VERSION "CHUFENG J1939 CAN database (generated from XTOOL HD_CHUFENGDEV data)"

NS_ :

BS_:

BU_: BMS MCU VCU ICM AC CPS ADAS BAT BMSW

BO_ 2364539985 ICM_F004: 8 ICM
 SG_ ICM_F00451_01_0A : 24|16@1+ (0.5,-16000) [-16000|16767.5] "rpm" ICM

BO_ 2365529937 BMS_FF1F: 8 BMS
 SG_ BMS_FF1F51_01_01 : 6|2@1+ (1,0) [0|3] "" BMS

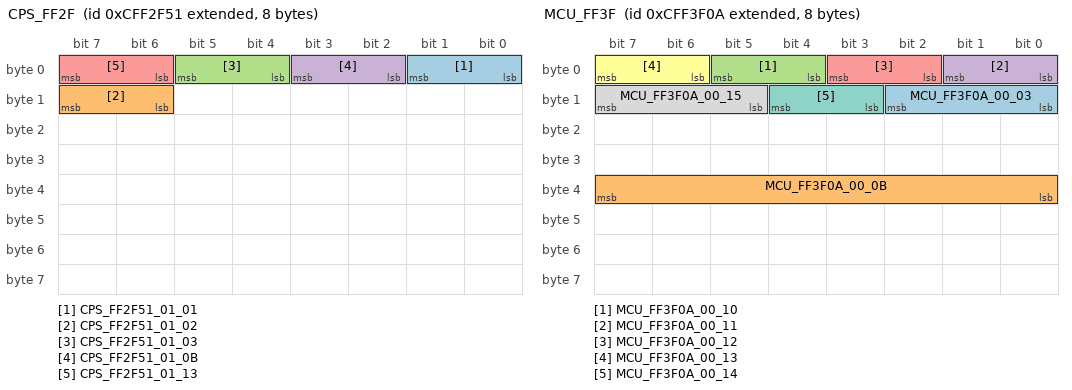
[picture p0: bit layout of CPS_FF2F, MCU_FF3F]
BO_ 2365534033 CPS_FF2F: 8 CPS
 SG_ CPS_FF2F51_01_01 : 0|2@1+ (1,0) [0|3] "" CPS
 SG_ CPS_FF2F51_01_02 : 14|2@1+ (1,0) [0|3] "" CPS
 SG_ CPS_FF2F51_01_03 : 4|2@1+ (1,0) [0|3] "" CPS
 SG_ CPS_FF2F51_01_0B : 2|2@1+ (1,0) [0|3] "" CPS
 SG_ CPS_FF2F51_01_13 : 6|2@1+ (1,0) [0|3] "" CPS

BO_ 2365537802 MCU_FF3E: 8 MCU
 SG_ MCU_FF3E0A_00_09 : 0|16@1+ (0.5,-16000) [-16000|16767.5] "rpm" MCU

BO_ 2365538058 MCU_FF3F: 8 MCU
 SG_ MCU_FF3F0A_00_03 : 8|3@1+ (1,0) [0|7] "" MCU
 SG_ MCU_FF3F0A_00_0B : 32|8@1+ (1,-125) [-125|130] "%" MCU
 SG_ MCU_FF3F0A_00_10 : 4|2@1+ (1,0) [0|3] "" MCU
 SG_ MCU_FF3F0A_00_11 : 0|2@1+ (1,0) [0|3] "" MCU
 SG_ MCU_FF3F0A_00_12 : 2|2@1+ (1,0) [0|3] "" MCU
 SG_ MCU_FF3F0A_00_13 : 6|2@1+ (1,0) [0|3] "" MCU
 SG_ MCU_FF3F0A_00_14 : 11|2@1+ (1,0) [0|3] "" MCU
 SG_ MCU_FF3F0A_00_15 : 13|3@1+ (1,0) [0|7] "" MCU

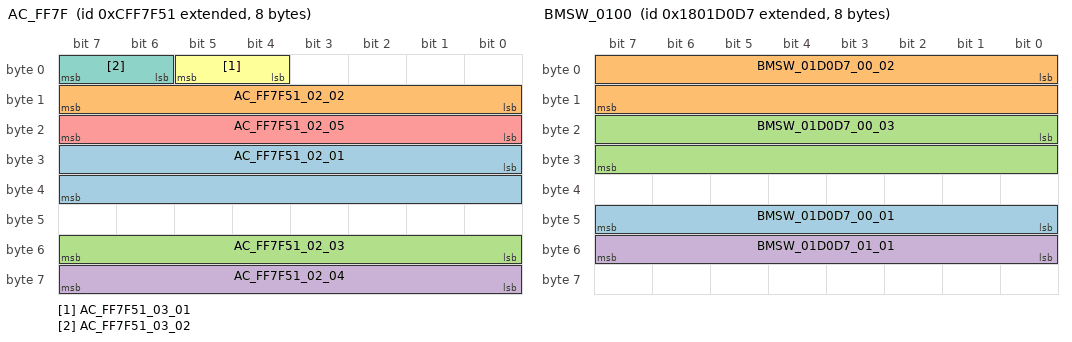
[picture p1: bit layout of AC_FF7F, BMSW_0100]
BO_ 2365554513 AC_FF7F: 8 AC
 SG_ AC_FF7F51_02_01 : 24|16@1+ (0.25,0) [0|16383.75] "rpm" AC
 SG_ AC_FF7F51_02_02 : 8|8@1+ (0.4,0) [0|102] "%" AC
 SG_ AC_FF7F51_02_03 : 48|8@1+ (200,0) [0|51000] "W" AC
 SG_ AC_FF7F51_02_04 : 56|8@1+ (200,0) [0|51000] "W" AC
 SG_ AC_FF7F51_02_05 : 16|8@1+ (1,-40) [-40|215] "℃" AC
 SG_ AC_FF7F51_03_01 : 4|2@1+ (1,0) [0|3] "" AC
 SG_ AC_FF7F51_03_02 : 6|2@1+ (1,0) [0|3] "" AC

BO_ 2550255831 BMSW_0100: 8 BMSW
 SG_ BMSW_01D0D7_00_01 : 40|8@1+ (1,0) [0|255] "" BMSW
 SG_ BMSW_01D0D7_00_02 : 0|16@1+ (1,0) [0|65535] "KΩ" BMSW
 SG_ BMSW_01D0D7_00_03 : 16|16@1+ (1,0) [0|65535] "KΩ" BMSW
 SG_ BMSW_01D0D7_01_01 : 48|8@1+ (1,0) [0|255] "" BMSW

BO_ 2550265081 ADAS_0100: 8 ADAS
 SG_ ADAS_01F4F9_02_01 : 8|8@1+ (1,0) [0|255] "" ADAS
 SG_ ADAS_01F4F9_02_02 : 0|8@1+ (1,0) [0|255] "" ADAS

BO_ 2565865553 ICM_F000: 8 ICM
 SG_ ICM_F00051_02_02 : 26|2@1+ (1,0) [0|3] "" ICM

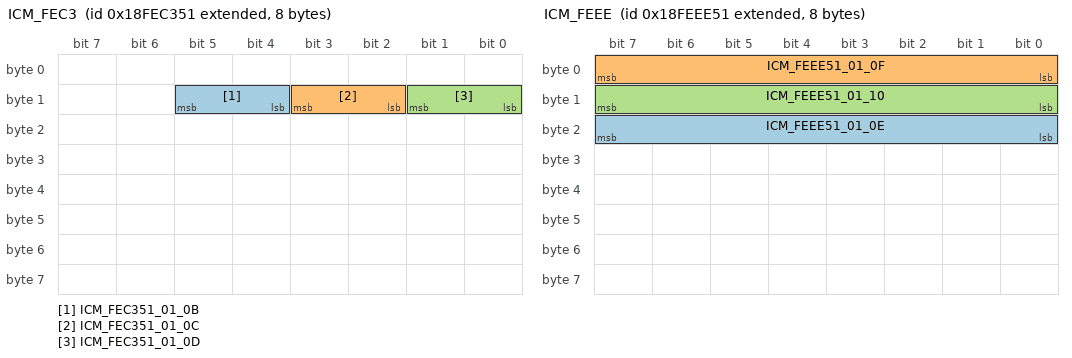
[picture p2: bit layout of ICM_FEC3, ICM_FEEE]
BO_ 2566832977 ICM_FEC3: 8 ICM
 SG_ ICM_FEC351_01_0B : 12|2@1+ (1,0) [0|3] "" ICM
 SG_ ICM_FEC351_01_0C : 10|2@1+ (1,0) [0|3] "" ICM
 SG_ ICM_FEC351_01_0D : 8|2@1+ (1,0) [0|3] "" ICM

BO_ 2566843985 ICM_FEEE: 8 ICM
 SG_ ICM_FEEE51_01_0E : 16|8@1+ (1,-40) [-40|215] "℃" ICM
 SG_ ICM_FEEE51_01_0F : 0|8@1+ (1,-40) [-40|215] "℃" ICM
 SG_ ICM_FEEE51_01_10 : 8|8@1+ (1,-40) [-40|215] "℃" ICM

BO_ 2566844753 ICM_FEF1: 8 ICM
 SG_ ICM_FEF151_01_01 : 8|16@1+ (0.00390625,0) [0|255.996094] "km/h" ICM

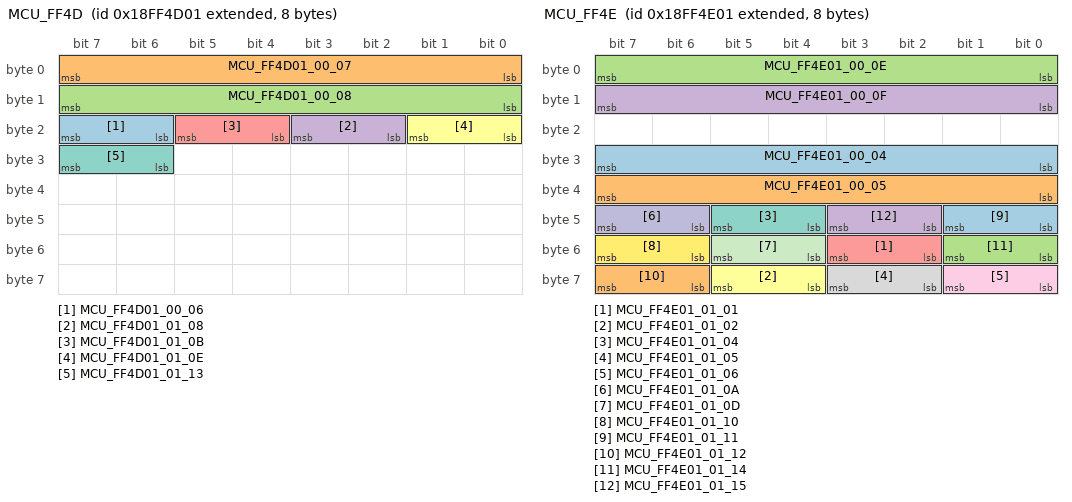
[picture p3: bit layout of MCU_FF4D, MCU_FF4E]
BO_ 2566868225 MCU_FF4D: 8 MCU
 SG_ MCU_FF4D01_00_06 : 22|2@1+ (1,0) [0|3] "" MCU
 SG_ MCU_FF4D01_00_07 : 0|8@1+ (1,0) [0|255] "" MCU
 SG_ MCU_FF4D01_00_08 : 8|8@1+ (1,0) [0|255] "" MCU
 SG_ MCU_FF4D01_01_08 : 18|2@1+ (1,0) [0|3] "" MCU
 SG_ MCU_FF4D01_01_0B : 20|2@1+ (1,0) [0|3] "" MCU
 SG_ MCU_FF4D01_01_0E : 16|2@1+ (1,0) [0|3] "" MCU
 SG_ MCU_FF4D01_01_13 : 30|2@1+ (1,0) [0|3] "" MCU

BO_ 2566868481 MCU_FF4E: 8 MCU
 SG_ MCU_FF4E01_00_04 : 24|8@1+ (1,-125) [-125|130] "%" MCU
 SG_ MCU_FF4E01_00_05 : 32|8@1+ (1,-125) [-125|130] "%" MCU
 SG_ MCU_FF4E01_00_0E : 0|8@1+ (1,-40) [-40|215] "℃" MCU
 SG_ MCU_FF4E01_00_0F : 8|8@1+ (1,-40) [-40|215] "℃" MCU
 SG_ MCU_FF4E01_01_01 : 50|2@1+ (1,0) [0|3] "" MCU
 SG_ MCU_FF4E01_01_02 : 60|2@1+ (1,0) [0|3] "" MCU
 SG_ MCU_FF4E01_01_04 : 44|2@1+ (1,0) [0|3] "" MCU
 SG_ MCU_FF4E01_01_05 : 58|2@1+ (1,0) [0|3] "" MCU
 SG_ MCU_FF4E01_01_06 : 56|2@1+ (1,0) [0|3] "" MCU
 SG_ MCU_FF4E01_01_0A : 46|2@1+ (1,0) [0|3] "" MCU
 SG_ MCU_FF4E01_01_0D : 52|2@1+ (1,0) [0|3] "" MCU
 SG_ MCU_FF4E01_01_10 : 54|2@1+ (1,0) [0|3] "" MCU
 SG_ MCU_FF4E01_01_11 : 40|2@1+ (1,0) [0|3] "" MCU
 SG_ MCU_FF4E01_01_12 : 62|2@1+ (1,0) [0|3] "" MCU
 SG_ MCU_FF4E01_01_14 : 48|2@1+ (1,0) [0|3] "" MCU
 SG_ MCU_FF4E01_01_15 : 42|2@1+ (1,0) [0|3] "" MCU

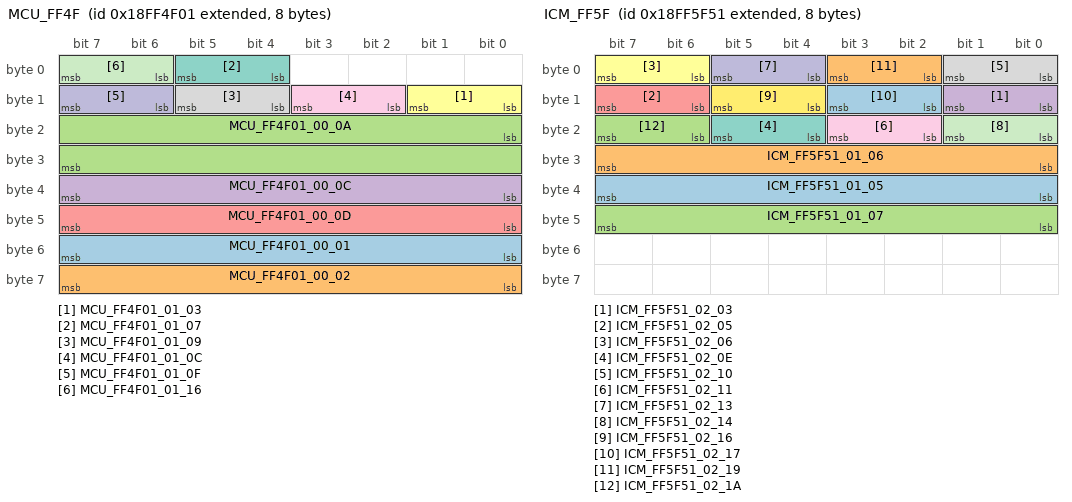
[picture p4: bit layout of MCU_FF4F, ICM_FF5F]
BO_ 2566868737 MCU_FF4F: 8 MCU
 SG_ MCU_FF4F01_00_01 : 48|8@1+ (3.2,0) [0|816] "V" MCU
 SG_ MCU_FF4F01_00_02 : 56|8@1+ (4,-500) [-500|520] "A" MCU
 SG_ MCU_FF4F01_00_0A : 16|16@1+ (0.5,-16000) [-16000|16767.5] "rpm" MCU
 SG_ MCU_FF4F01_00_0C : 32|8@1+ (1,-125) [-125|130] "%" MCU
 SG_ MCU_FF4F01_00_0D : 40|8@1+ (1,-125) [-125|130] "%" MCU
 SG_ MCU_FF4F01_01_03 : 8|2@1+ (1,0) [0|3] "" MCU
 SG_ MCU_FF4F01_01_07 : 4|2@1+ (1,0) [0|3] "" MCU
 SG_ MCU_FF4F01_01_09 : 12|2@1+ (1,0) [0|3] "" MCU
 SG_ MCU_FF4F01_01_0C : 10|2@1+ (1,0) [0|3] "" MCU
 SG_ MCU_FF4F01_01_0F : 14|2@1+ (1,0) [0|3] "" MCU
 SG_ MCU_FF4F01_01_16 : 6|2@1+ (1,0) [0|3] "" MCU

BO_ 2566872913 ICM_FF5F: 8 ICM
 SG_ ICM_FF5F51_01_05 : 32|8@1+ (4,-500) [-500|520] "A" ICM
 SG_ ICM_FF5F51_01_06 : 24|8@1+ (3.2,0) [0|816] "V" ICM
 SG_ ICM_FF5F51_01_07 : 40|8@1+ (2,0) [0|510] "km" ICM
 SG_ ICM_FF5F51_02_03 : 8|2@1+ (1,0) [0|3] "" ICM
 SG_ ICM_FF5F51_02_05 : 14|2@1+ (1,0) [0|3] "" ICM
 SG_ ICM_FF5F51_02_06 : 6|2@1+ (1,0) [0|3] "" ICM
 SG_ ICM_FF5F51_02_0E : 20|2@1+ (1,0) [0|3] "" ICM
 SG_ ICM_FF5F51_02_10 : 0|2@1+ (1,0) [0|3] "" ICM
 SG_ ICM_FF5F51_02_11 : 18|2@1+ (1,0) [0|3] "" ICM
 SG_ ICM_FF5F51_02_13 : 4|2@1+ (1,0) [0|3] "" ICM
 SG_ ICM_FF5F51_02_14 : 16|2@1+ (1,0) [0|3] "" ICM
 SG_ ICM_FF5F51_02_16 : 12|2@1+ (1,0) [0|3] "" ICM
 SG_ ICM_FF5F51_02_17 : 10|2@1+ (1,0) [0|3] "" ICM
 SG_ ICM_FF5F51_02_19 : 2|2@1+ (1,0) [0|3] "" ICM
 SG_ ICM_FF5F51_02_1A : 22|2@1+ (1,0) [0|3] "" ICM

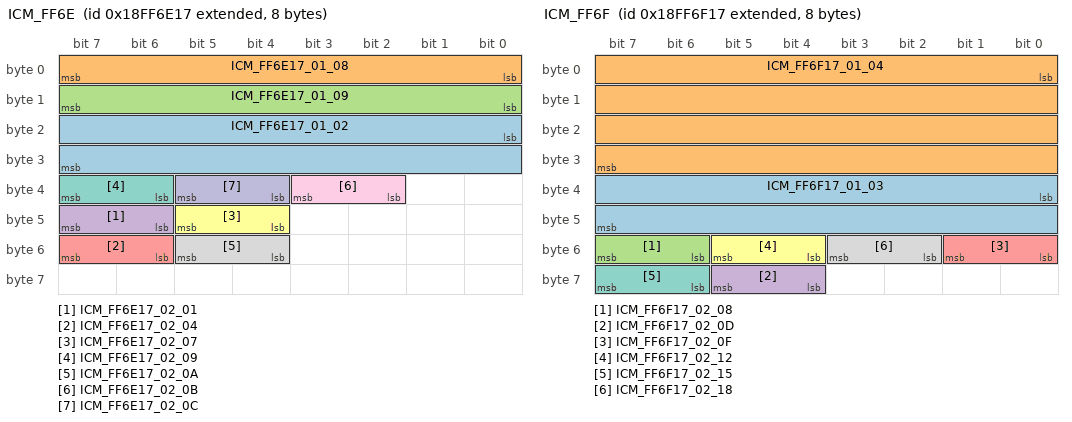
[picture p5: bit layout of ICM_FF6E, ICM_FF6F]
BO_ 2566876695 ICM_FF6E: 8 ICM
 SG_ ICM_FF6E17_01_02 : 16|16@1+ (0.00390625,0) [0|255.996094] "km/h" ICM
 SG_ ICM_FF6E17_01_08 : 0|8@1+ (10,0) [0|2550] "Kpa" ICM
 SG_ ICM_FF6E17_01_09 : 8|8@1+ (10,0) [0|2550] "Kpa" ICM
 SG_ ICM_FF6E17_02_01 : 46|2@1+ (1,0) [0|3] "" ICM
 SG_ ICM_FF6E17_02_04 : 54|2@1+ (1,0) [0|3] "" ICM
 SG_ ICM_FF6E17_02_07 : 44|2@1+ (1,0) [0|3] "" ICM
 SG_ ICM_FF6E17_02_09 : 38|2@1+ (1,0) [0|3] "" ICM
 SG_ ICM_FF6E17_02_0A : 52|2@1+ (1,0) [0|3] "" ICM
 SG_ ICM_FF6E17_02_0B : 34|2@1+ (1,0) [0|3] "" ICM
 SG_ ICM_FF6E17_02_0C : 36|2@1+ (1,0) [0|3] "" ICM

BO_ 2566876951 ICM_FF6F: 8 ICM
 SG_ ICM_FF6F17_01_03 : 32|16@1+ (0.1,0) [0|6553.5] "km" ICM
 SG_ ICM_FF6F17_01_04 : 0|32@1+ (1,0) [0|4294967295] "km" ICM
 SG_ ICM_FF6F17_02_08 : 54|2@1+ (1,0) [0|3] "" ICM
 SG_ ICM_FF6F17_02_0D : 60|2@1+ (1,0) [0|3] "" ICM
 SG_ ICM_FF6F17_02_0F : 48|2@1+ (1,0) [0|3] "" ICM
 SG_ ICM_FF6F17_02_12 : 52|2@1+ (1,0) [0|3] "" ICM
 SG_ ICM_FF6F17_02_15 : 62|2@1+ (1,0) [0|3] "" ICM
 SG_ ICM_FF6F17_02_18 : 50|2@1+ (1,0) [0|3] "" ICM

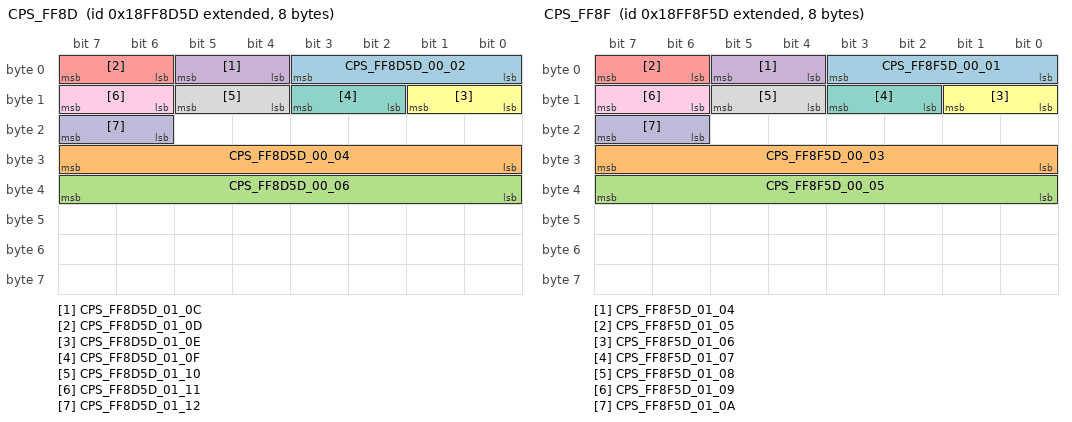
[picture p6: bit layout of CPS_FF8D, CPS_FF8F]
BO_ 2566884701 CPS_FF8D: 8 CPS
 SG_ CPS_FF8D5D_00_02 : 0|4@1+ (1,0) [0|15] "" CPS
 SG_ CPS_FF8D5D_00_04 : 24|8@1+ (2,0) [0|510] "V" CPS
 SG_ CPS_FF8D5D_00_06 : 32|8@1+ (1,-40) [-40|215] "℃" CPS
 SG_ CPS_FF8D5D_01_0C : 4|2@1+ (1,0) [0|3] "" CPS
 SG_ CPS_FF8D5D_01_0D : 6|2@1+ (1,0) [0|3] "" CPS
 SG_ CPS_FF8D5D_01_0E : 8|2@1+ (1,0) [0|3] "" CPS
 SG_ CPS_FF8D5D_01_0F : 10|2@1+ (1,0) [0|3] "" CPS
 SG_ CPS_FF8D5D_01_10 : 12|2@1+ (1,0) [0|3] "" CPS
 SG_ CPS_FF8D5D_01_11 : 14|2@1+ (1,0) [0|3] "" CPS
 SG_ CPS_FF8D5D_01_12 : 22|2@1+ (1,0) [0|3] "" CPS

BO_ 2566885213 CPS_FF8F: 8 CPS
 SG_ CPS_FF8F5D_00_01 : 0|4@1+ (1,0) [0|15] "" CPS
 SG_ CPS_FF8F5D_00_03 : 24|8@1+ (2,0) [0|510] "V" CPS
 SG_ CPS_FF8F5D_00_05 : 32|8@1+ (1,-40) [-40|215] "℃" CPS
 SG_ CPS_FF8F5D_01_04 : 4|2@1+ (1,0) [0|3] "" CPS
 SG_ CPS_FF8F5D_01_05 : 6|2@1+ (1,0) [0|3] "" CPS
 SG_ CPS_FF8F5D_01_06 : 8|2@1+ (1,0) [0|3] "" CPS
 SG_ CPS_FF8F5D_01_07 : 10|2@1+ (1,0) [0|3] "" CPS
 SG_ CPS_FF8F5D_01_08 : 12|2@1+ (1,0) [0|3] "" CPS
 SG_ CPS_FF8F5D_01_09 : 14|2@1+ (1,0) [0|3] "" CPS
 SG_ CPS_FF8F5D_01_0A : 22|2@1+ (1,0) [0|3] "" CPS

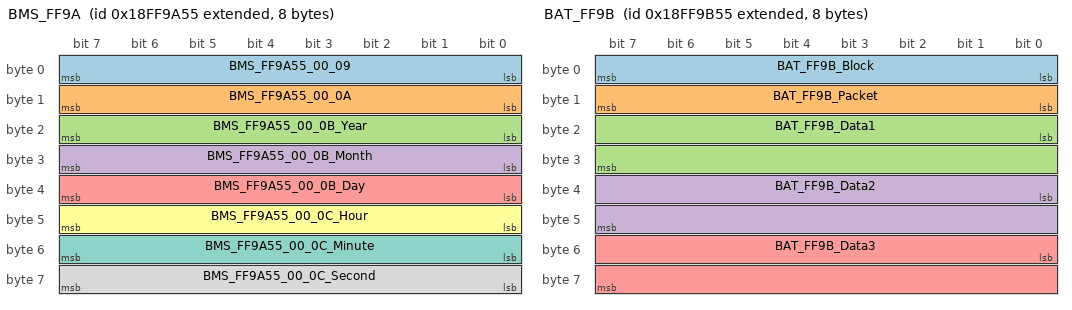
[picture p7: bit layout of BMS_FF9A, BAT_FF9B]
BO_ 2566888021 BMS_FF9A: 8 BMS
 SG_ BMS_FF9A55_00_09 : 0|8@1+ (1,0) [0|255] "" BMS
 SG_ BMS_FF9A55_00_0A : 8|8@1+ (1,0) [0|255] "" BMS
 SG_ BMS_FF9A55_00_0B_Year : 16|8@1+ (1,0) [0|255] "" BMS
 SG_ BMS_FF9A55_00_0B_Month : 24|8@1+ (1,0) [0|255] "" BMS
 SG_ BMS_FF9A55_00_0B_Day : 32|8@1+ (1,0) [0|255] "" BMS
 SG_ BMS_FF9A55_00_0C_Hour : 40|8@1+ (1,0) [0|255] "" BMS
 SG_ BMS_FF9A55_00_0C_Minute : 48|8@1+ (1,0) [0|255] "" BMS
 SG_ BMS_FF9A55_00_0C_Second : 56|8@1+ (1,0) [0|255] "" BMS

BO_ 2566888277 BAT_FF9B: 8 BAT
 SG_ BAT_FF9B_Block : 0|8@1+ (1,0) [0|255] "" BAT
 SG_ BAT_FF9B_Packet : 8|8@1+ (1,0) [0|255] "" BAT
 SG_ BAT_FF9B_Data1 : 16|16@1+ (1,0) [0|65535] "" BAT
 SG_ BAT_FF9B_Data2 : 32|16@1+ (1,0) [0|65535] "" BAT
 SG_ BAT_FF9B_Data3 : 48|16@1+ (1,0) [0|65535] "" BAT

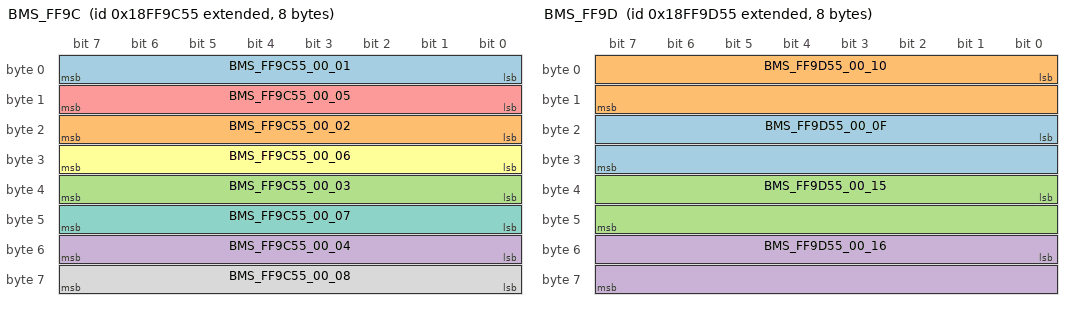
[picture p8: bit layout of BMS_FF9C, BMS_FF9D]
BO_ 2566888533 BMS_FF9C: 8 BMS
 SG_ BMS_FF9C55_00_01 : 0|8@1+ (1,0) [0|255] "" BMS
 SG_ BMS_FF9C55_00_02 : 16|8@1+ (1,0) [0|255] "" BMS
 SG_ BMS_FF9C55_00_03 : 32|8@1+ (1,0) [0|255] "" BMS
 SG_ BMS_FF9C55_00_04 : 48|8@1+ (1,0) [0|255] "" BMS
 SG_ BMS_FF9C55_00_05 : 8|8@1+ (1,0) [0|255] "" BMS
 SG_ BMS_FF9C55_00_06 : 24|8@1+ (1,0) [0|255] "" BMS
 SG_ BMS_FF9C55_00_07 : 40|8@1+ (1,0) [0|255] "" BMS
 SG_ BMS_FF9C55_00_08 : 56|8@1+ (1,0) [0|255] "" BMS

BO_ 2566888789 BMS_FF9D: 8 BMS
 SG_ BMS_FF9D55_00_0F : 16|16@1+ (0.01999999999998181,-640) [-640|670.7] "A" BMS
 SG_ BMS_FF9D55_00_10 : 0|16@1+ (0.02,0) [0|1310.7] "V" BMS
 SG_ BMS_FF9D55_00_15 : 32|16@1+ (0.01,0) [0|655.35] "A" BMS
 SG_ BMS_FF9D55_00_16 : 48|16@1+ (0.01,0) [0|655.35] "A" BMS

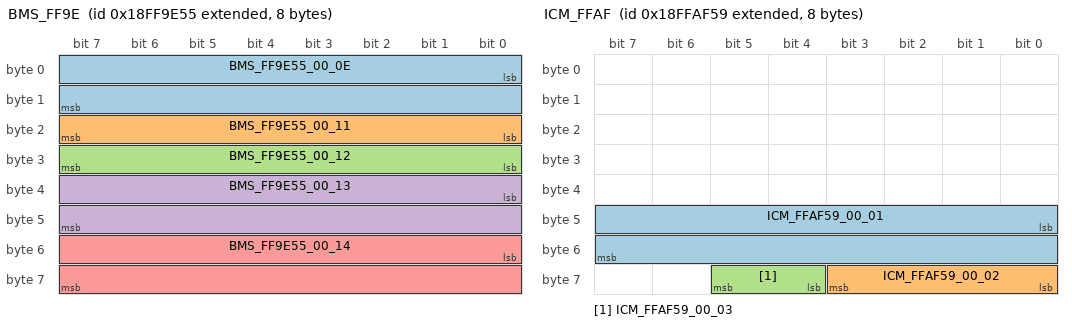
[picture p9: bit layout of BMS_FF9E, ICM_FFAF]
BO_ 2566889045 BMS_FF9E: 8 BMS
 SG_ BMS_FF9E55_00_0E : 0|16@1+ (1,0) [0|65535] "KΩ" BMS
 SG_ BMS_FF9E55_00_11 : 16|8@1+ (1,-40) [-40|215] "℃" BMS
 SG_ BMS_FF9E55_00_12 : 24|8@1+ (1,-40) [-40|215] "℃" BMS
 SG_ BMS_FF9E55_00_13 : 32|16@1+ (0.001,0) [0|65.535] "V" BMS
 SG_ BMS_FF9E55_00_14 : 48|16@1+ (0.001,0) [0|65.535] "V" BMS

BO_ 2566889301 BMS_FF9F: 8 BMS
 SG_ BMS_FF9F55_00_0D : 40|8@1+ (0.4,0) [0|102] "%" BMS
 SG_ BMS_FF9F55_01_02 : 12|2@1+ (1,0) [0|3] "" BMS
 SG_ BMS_FF9F55_01_03 : 4|2@1+ (1,0) [0|3] "" BMS
 SG_ BMS_FF9F55_01_04 : 38|2@1+ (1,0) [0|3] "" BMS
 SG_ BMS_FF9F55_01_05 : 14|2@1+ (1,0) [0|3] "" BMS
 SG_ BMS_FF9F55_01_06 : 34|2@1+ (1,0) [0|3] "" BMS
 SG_ BMS_FF9F55_01_07 : 24|2@1+ (1,0) [0|3] "" BMS
 SG_ BMS_FF9F55_01_08 : 18|2@1+ (1,0) [0|3] "" BMS
 SG_ BMS_FF9F55_01_09 : 36|2@1+ (1,0) [0|3] "" BMS
 SG_ BMS_FF9F55_01_0A : 54|2@1+ (1,0) [0|3] "" BMS
 SG_ BMS_FF9F55_01_0B : 20|2@1+ (1,0) [0|3] "" BMS
 SG_ BMS_FF9F55_01_0C : 26|2@1+ (1,0) [0|3] "" BMS
 SG_ BMS_FF9F55_01_0D : 6|2@1+ (1,0) [0|3] "" BMS
 SG_ BMS_FF9F55_01_0E : 8|2@1+ (1,0) [0|3] "" BMS
 SG_ BMS_FF9F55_01_0F : 0|2@1+ (1,0) [0|3] "" BMS
 SG_ BMS_FF9F55_01_10 : 10|2@1+ (1,0) [0|3] "" BMS
 SG_ BMS_FF9F55_01_11 : 22|2@1+ (1,0) [0|3] "" BMS
 SG_ BMS_FF9F55_01_12 : 28|2@1+ (1,0) [0|3] "" BMS
 SG_ BMS_FF9F55_01_13 : 32|2@1+ (1,0) [0|3] "" BMS
 SG_ BMS_FF9F55_01_14 : 16|2@1+ (1,0) [0|3] "" BMS
 SG_ BMS_FF9F55_01_16 : 2|2@1+ (1,0) [0|3] "" BMS

BO_ 2566893401 ICM_FFAF: 8 ICM
 SG_ ICM_FFAF59_00_01 : 40|16@1+ (1,0) [0|65535] "KΩ" ICM
 SG_ ICM_FFAF59_00_02 : 56|4@1+ (1,0) [0|15] "" ICM
 SG_ ICM_FFAF59_00_03 : 60|2@1+ (1,0) [0|3] "" ICM

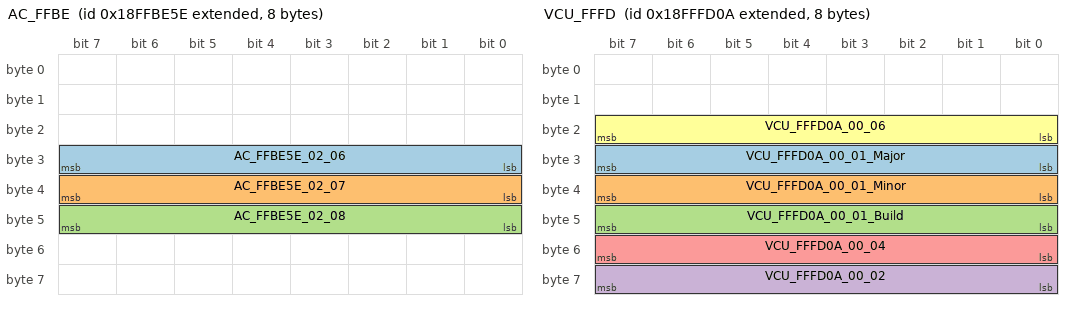
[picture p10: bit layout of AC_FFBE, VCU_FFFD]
BO_ 2566897246 AC_FFBE: 8 AC
 SG_ AC_FFBE5E_02_06 : 24|8@1+ (1,-40) [-40|215] "℃" AC
 SG_ AC_FFBE5E_02_07 : 32|8@1+ (1,-40) [-40|215] "℃" AC
 SG_ AC_FFBE5E_02_08 : 40|8@1+ (1,-40) [-40|215] "℃" AC

BO_ 2566913290 VCU_FFFD: 8 VCU
 SG_ VCU_FFFD0A_00_01_Major : 24|8@1+ (1,0) [0|255] "" VCU
 SG_ VCU_FFFD0A_00_01_Minor : 32|8@1+ (1,0) [0|255] "" VCU
 SG_ VCU_FFFD0A_00_01_Build : 40|8@1+ (1,0) [0|255] "" VCU
 SG_ VCU_FFFD0A_00_02 : 56|8@1+ (1,0) [0|255] "" VCU
 SG_ VCU_FFFD0A_00_04 : 48|8@1+ (1,-125) [-125|130] "%" VCU
 SG_ VCU_FFFD0A_00_06 : 16|8@1+ (0.39215686274509803,0) [0|100] "%" VCU

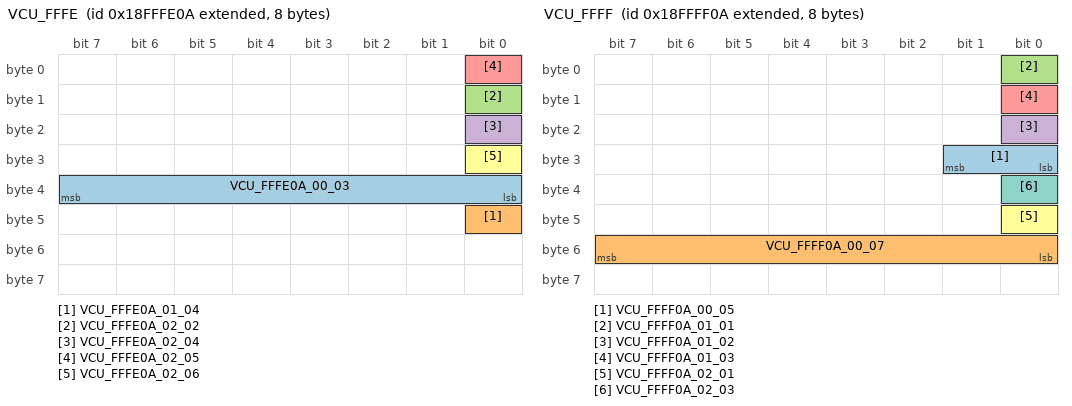
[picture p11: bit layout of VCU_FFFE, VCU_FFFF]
BO_ 2566913546 VCU_FFFE: 8 VCU
 SG_ VCU_FFFE0A_00_03 : 32|8@1+ (1,0) [0|255] "" VCU
 SG_ VCU_FFFE0A_01_04 : 40|1@1+ (1,0) [0|1] "" VCU
 SG_ VCU_FFFE0A_02_02 : 8|1@1+ (1,0) [0|1] "" VCU
 SG_ VCU_FFFE0A_02_04 : 16|1@1+ (1,0) [0|1] "" VCU
 SG_ VCU_FFFE0A_02_05 : 0|1@1+ (1,0) [0|1] "" VCU
 SG_ VCU_FFFE0A_02_06 : 24|1@1+ (1,0) [0|1] "" VCU

BO_ 2566913802 VCU_FFFF: 8 VCU
 SG_ VCU_FFFF0A_00_05 : 24|2@1+ (1,0) [0|3] "" VCU
 SG_ VCU_FFFF0A_00_07 : 48|8@1+ (0.39215686274509803,0) [0|100] "%" VCU
 SG_ VCU_FFFF0A_01_01 : 0|1@1+ (1,0) [0|1] "" VCU
 SG_ VCU_FFFF0A_01_02 : 16|1@1+ (1,0) [0|1] "" VCU
 SG_ VCU_FFFF0A_01_03 : 8|1@1+ (1,0) [0|1] "" VCU
 SG_ VCU_FFFF0A_02_01 : 40|1@1+ (1,0) [0|1] "" VCU
 SG_ VCU_FFFF0A_02_03 : 32|1@1+ (1,0) [0|1] "" VCU

CM_ "CHUFENG 楚风 J1939 CAN 数据库";
CM_ "CAN 250kbps, 29-bit extended frames. 由 HD_CHUFENGDEV/data/CN_DS.txt + DataSteam_Option.txt 自动生成。";
CM_ "信号名 <系统>_<CANID后6位>_<b3>_<b5> 与 CN_DS.txt 数据流 id 一一对应; 中文名见信号注释。";
CM_ "18FF9B55 (BAT_FF9B) 为分块/请求索引数据, 按块号+包号+3个16位数据生成通用块信号。";
CM_ BO_ 2364539985 "ICM 仪表 / 绝缘监测, CAN ID 0x0CF00451, PGN 0xF004, SA 0x51";
CM_ SG_ 2364539985 ICM_F00451_01_0A "电机转速 (原始算法: (BYTE[4]*256+BYTE[3])*0.5-16000)";
CM_ BO_ 2365529937 "BMS 电池管理系统, CAN ID 0x0CFF1F51, PGN 0xFF1F, SA 0x51";
CM_ SG_ 2365529937 BMS_FF1F51_01_01 "BMS断开主负 (原始算法: if((BYTE[0]&0xC0)==0x40) @0;else @1;)";
CM_ BO_ 2365534033 "CPS 组合电源 (气泵/油泵), CAN ID 0x0CFF2F51, PGN 0xFF2F, SA 0x51";
CM_ SG_ 2365534033 CPS_FF2F51_01_01 "预留电源模块使能信号 (原始算法: if((BYTE[0]&0x03)==0x01) @0;else @1;)";
CM_ SG_ 2365534033 CPS_FF2F51_01_02 "预留电源模块使能信号2 (原始算法: if((BYTE[1]&0xC0)==0x40) @0;else @1;)";
CM_ SG_ 2365534033 CPS_FF2F51_01_03 "供油泵DCAC使能信号 (原始算法: if((BYTE[0]&0x30)==0x10) @0;else @1;)";
CM_ SG_ 2365534033 CPS_FF2F51_01_0B "供气泵DCAC使能信号 (原始算法: if((BYTE[0]&0x0C)==0x04) @0;else @1;)";
CM_ SG_ 2365534033 CPS_FF2F51_01_13 "供低压DCDC使能信号 (原始算法: if((BYTE[0]&0xC0)==0x40) @0;else @1;)";
CM_ BO_ 2365537802 "MCU 电机控制器, CAN ID 0x0CFF3E0A, PGN 0xFF3E, SA 0x0A";
CM_ SG_ 2365537802 MCU_FF3E0A_00_09 "电机1需输出的转速/转速限值 (原始算法: (BYTE[1]*256+BYTE[0])*0.5-16000)";
CM_ BO_ 2365538058 "MCU 电机控制器, CAN ID 0x0CFF3F0A, PGN 0xFF3F, SA 0x0A";
CM_ SG_ 2365538058 MCU_FF3F0A_00_03 "生命信号帧 (原始算法: BYTE[1]&0x07)";
CM_ SG_ 2365538058 MCU_FF3F0A_00_0B "电机1需输出的转矩/转矩限值 (原始算法: BYTE[4]-125)";
CM_ SG_ 2365538058 MCU_FF3F0A_00_10 "VCU-MCU允许自放电 (原始算法: if((BYTE[0]&0x30)==0x10) @0;else @1;)";
CM_ SG_ 2365538058 MCU_FF3F0A_00_11 "电机驱动模式 (原始算法: if((BYTE[0]&0x03)==0x01) @0;else @1;)";
CM_ SG_ 2365538058 MCU_FF3F0A_00_12 "MCU依据此信号开PWM波 (原始算法: if((BYTE[0]&0x0C)==0x04) @0;else @1;)";
CM_ SG_ 2365538058 MCU_FF3F0A_00_13 "VCU-MCU预充电状态 (原始算法: if((BYTE[0]&0xC0)==0x40) @0;else @1;)";
CM_ SG_ 2365538058 MCU_FF3F0A_00_14 "刹车开关状态 (原始算法: if((BYTE[1]&0x18)==0x08) @0;else @1;)";
CM_ SG_ 2365538058 MCU_FF3F0A_00_15 "档位需求 (原始算法: if((BYTE[1]&0xE0)==0x40) @0;else if((BYTE[1]&0xE0)==0x80) @1;else @2;)";
CM_ BO_ 2365554513 "AC 空调, CAN ID 0x0CFF7F51, PGN 0xFF7F, SA 0x51";
CM_ SG_ 2365554513 AC_FF7F51_02_01 "空调压缩机设定转速 (原始算法: (BYTE[4]*256+BYTE[3])/4.00)";
CM_ SG_ 2365554513 AC_FF7F51_02_02 "需求的空调功率 (原始算法: BYTE[1]*0.4)";
CM_ SG_ 2365554513 AC_FF7F51_02_03 "空调最大制冷功率 (原始算法: BYTE[6]*200)";
CM_ SG_ 2365554513 AC_FF7F51_02_04 "空调最大制热功率 (原始算法: BYTE[7]*200)";
CM_ SG_ 2365554513 AC_FF7F51_02_05 "空调设定温度 (原始算法: BYTE[2]-40)";
CM_ SG_ 2365554513 AC_FF7F51_03_01 "空调功率控制请求 (原始算法: if((BYTE[0]&0x30)==0x10) @0;else @1;)";
CM_ SG_ 2365554513 AC_FF7F51_03_02 "空调工作使能请求 (原始算法: if((BYTE[0]&0xC0)==0x40) @0;else @1;)";
CM_ BO_ 2550255831 "BMS_WOTEMA 沃特玛 BMS, CAN ID 0x1801D0D7, PGN 0x0100, SA 0xD7";
CM_ SG_ 2550255831 BMSW_01D0D7_00_01 "绝缘检测Life值 (原始算法: BYTE[5])";
CM_ SG_ 2550255831 BMSW_01D0D7_00_02 "正端对地绝缘电阻 (原始算法: BYTE[1]*256+BYTE[0])";
CM_ SG_ 2550255831 BMSW_01D0D7_00_03 "负端对地绝缘电阻 (原始算法: BYTE[3]*256+BYTE[2])";
CM_ SG_ 2550255831 BMSW_01D0D7_01_01 "绝缘模块故障状态 (原始算法: if(BYTE[6]==0x55) @0;else @1;)";
CM_ BO_ 2550265081 "ADAS 远程监控 / 远程锁车, CAN ID 0x1801F4F9, PGN 0x0100, SA 0xF9";
CM_ SG_ 2550265081 ADAS_01F4F9_02_01 "锁车指令 (原始算法: if(BYTE[1]==0x02) @0;else @1;)";
CM_ SG_ 2550265081 ADAS_01F4F9_02_02 "远程监控模块状态 (原始算法: if(BYTE[0]==0x02) @0;else @1;)";
CM_ BO_ 2565865553 "ICM 仪表 / 绝缘监测, CAN ID 0x18F00051, PGN 0xF000, SA 0x51";
CM_ SG_ 2565865553 ICM_F00051_02_02 "电机制动有效信号 (原始算法: if((BYTE[3]&0x0C)==0x04) @0;else @1;)";
CM_ BO_ 2566832977 "ICM 仪表 / 绝缘监测, CAN ID 0x18FEC351, PGN 0xFEC3, SA 0x51";
CM_ SG_ 2566832977 ICM_FEC351_01_0B "D档位 (原始算法: if((BYTE[1]&0x30)==0x10) @0;else if((BYTE[1]&0x30)==0x20) @1;else @2;)";
CM_ SG_ 2566832977 ICM_FEC351_01_0C "N档位 (原始算法: if((BYTE[1]&0x0C)==0x04) @0;else if((BYTE[1]&0x0C)==0x08) @1;else @2;)";
CM_ SG_ 2566832977 ICM_FEC351_01_0D "R档位 (原始算法: if((BYTE[1]&0x03)==0x01) @0;else if((BYTE[1]&0x03)==0x02) @1;else @2;)";
CM_ BO_ 2566843985 "ICM 仪表 / 绝缘监测, CAN ID 0x18FEEE51, PGN 0xFEEE, SA 0x51";
CM_ SG_ 2566843985 ICM_FEEE51_01_0E "电机温度 (原始算法: BYTE[2]-40)";
CM_ SG_ 2566843985 ICM_FEEE51_01_0F "冷却水温 (原始算法: BYTE[0]-40)";
CM_ SG_ 2566843985 ICM_FEEE51_01_10 "电机控制器IGBT温度 (原始算法: BYTE[1]-40)";
CM_ BO_ 2566844753 "ICM 仪表 / 绝缘监测, CAN ID 0x18FEF151, PGN 0xFEF1, SA 0x51";
CM_ SG_ 2566844753 ICM_FEF151_01_01 "车速 (原始算法: (BYTE[2]*256+BYTE[1])*0.00390625)";
CM_ BO_ 2566868225 "MCU 电机控制器, CAN ID 0x18FF4D01, PGN 0xFF4D, SA 0x01";
CM_ SG_ 2566868225 MCU_FF4D01_00_06 "电机控制器自放电反馈 (原始算法: if((BYTE[2]>=0x00)&&(BYTE[2]<=0x3F)) @0;else if((BYTE[2]>=0x40)&&(BYTE[2]<=0x7F)) @1;else if((BYTE[2]>=0x80)&&(BYTE[2]<=0xBF)) @2;else @3;)";
CM_ SG_ 2566868225 MCU_FF4D01_00_07 "电机控制器硬件版本号 (原始算法: BYTE[0])";
CM_ SG_ 2566868225 MCU_FF4D01_00_08 "电机控制器软件版本号 (原始算法: BYTE[1])";
CM_ SG_ 2566868225 MCU_FF4D01_01_08 "母线电压传感器故障 (原始算法: if((BYTE[2]&0x0C)==0x08) @0;else @1;)";
CM_ SG_ 2566868225 MCU_FF4D01_01_0B "电机温度传感器故障 (原始算法: if((BYTE[2]&0x30)==0x10) @0;else @1;)";
CM_ SG_ 2566868225 MCU_FF4D01_01_0E "MCU硬件故障 (原始算法: if((BYTE[2]&0x03)==0x01) @0;else if((BYTE[2]&0x03)==0x02) @1;else @2;)";
CM_ SG_ 2566868225 MCU_FF4D01_01_13 "其他故障 (原始算法: if((BYTE[3]&0xC0)==0x40) @0;else if((BYTE[3]&0xC0)==0x80) @1;else @2;)";
CM_ BO_ 2566868481 "MCU 电机控制器, CAN ID 0x18FF4E01, PGN 0xFF4E, SA 0x01";
CM_ SG_ 2566868481 MCU_FF4E01_00_04 "电机当前允许最大正向转矩 (原始算法: BYTE[3]-125)";
CM_ SG_ 2566868481 MCU_FF4E01_00_05 "电机当前允许最大反向转矩 (原始算法: BYTE[4]-125)";
CM_ SG_ 2566868481 MCU_FF4E01_00_0E "电机控制器1的IGBT温度 (原始算法: BYTE[0]-40)";
CM_ SG_ 2566868481 MCU_FF4E01_00_0F "电机1温度 (原始算法: BYTE[1]-40)";
CM_ SG_ 2566868481 MCU_FF4E01_01_01 "电机过热 (原始算法: if((BYTE[6]&0x0C)==0x04) @0;else if((BYTE[6]&0x0C)==0x08) @1;else @2;)";
CM_ SG_ 2566868481 MCU_FF4E01_01_02 "电流传感器故障 (原始算法: if((BYTE[7]&0x30)==0x20) @0;else @1;)";
CM_ SG_ 2566868481 MCU_FF4E01_01_04 "IGBT过热 (原始算法: if((BYTE[5]&0x30)==0x10) @0;else if((BYTE[5]&0x30)==0x20) @1;else @2;)";
CM_ SG_ 2566868481 MCU_FF4E01_01_05 "旋变/速度传感器故障 (原始算法: if((BYTE[7]&0x0C)==0x08) @0;else @1;)";
CM_ SG_ 2566868481 MCU_FF4E01_01_06 "相电流平衡故障 (原始算法: if((BYTE[7]&0x03)==0x01) @0;else if((BYTE[7]&0x03)==0x02) @1;else @2;)";
CM_ SG_ 2566868481 MCU_FF4E01_01_0A "堵转保护 (原始算法: if((BYTE[5]&0xC0)==0x80) @0;else @1;)";
CM_ SG_ 2566868481 MCU_FF4E01_01_0D "电机超速 (原始算法: if((BYTE[6]&0x30)==0x10) @0;else if((BYTE[6]&0x30)==0x20) @1;else @2;)";
CM_ SG_ 2566868481 MCU_FF4E01_01_10 "相电流过流 (原始算法: if((BYTE[6]&0xC0)==0x40) @0;else if((BYTE[6]&0xC0)==0x80) @1;else @2;)";
CM_ SG_ 2566868481 MCU_FF4E01_01_11 "电机控制器/IGBT传感器故障 (原始算法: if((BYTE[5]&0x03)==0x01) @0;else @1;)";
CM_ SG_ 2566868481 MCU_FF4E01_01_12 "母线欠压故障 (原始算法: if((BYTE[7]&0xC0)==0x40) @0;else if((BYTE[7]&0xC0)==0x80) @1;else @2;)";
CM_ SG_ 2566868481 MCU_FF4E01_01_14 "MCU上报CAN通讯故障 (原始算法: if((BYTE[6]&0x03)==0x02) @0;else @1;)";
CM_ SG_ 2566868481 MCU_FF4E01_01_15 "低压欠压故障 (原始算法: if((BYTE[5]&0x0C)==0x08) @0;else @1;)";
CM_ BO_ 2566868737 "MCU 电机控制器, CAN ID 0x18FF4F01, PGN 0xFF4F, SA 0x01";
CM_ SG_ 2566868737 MCU_FF4F01_00_01 "电机侧直流母线电压 (原始算法: BYTE[6]*3.2)";
CM_ SG_ 2566868737 MCU_FF4F01_00_02 "电机侧直流母线电流 (原始算法: BYTE[7]*4-500)";
CM_ SG_ 2566868737 MCU_FF4F01_00_0A "电机1实际输出转速 (原始算法: (BYTE[3]*256+BYTE[2])*0.5-16000)";
CM_ SG_ 2566868737 MCU_FF4F01_00_0C "电机1转矩设定值 (原始算法: BYTE[4]-125)";
CM_ SG_ 2566868737 MCU_FF4F01_00_0D "电机1转矩输出值 (原始算法: BYTE[5]-125)";
CM_ SG_ 2566868737 MCU_FF4F01_01_03 "IGBT故障 (原始算法: if((BYTE[1]&0x03)==0x02) @0;else @1;)";
CM_ SG_ 2566868737 MCU_FF4F01_01_07 "驱动使能反馈 (原始算法: if((BYTE[0]&0x30)==0x10) @0;else @1;)";
CM_ SG_ 2566868737 MCU_FF4F01_01_09 "母线过流故障 (原始算法: if((BYTE[1]&0x30)==0x20) @0;else @1;)";
CM_ SG_ 2566868737 MCU_FF4F01_01_0C "MCU过温故障 (原始算法: if((BYTE[1]&0x0C)==0x04) @0;else if((BYTE[1]&0x0C)==0x08) @1;else @2;)";
CM_ SG_ 2566868737 MCU_FF4F01_01_0F "母线过压故障 (原始算法: if((BYTE[1]&0xC0)==0x40) @0;else if((BYTE[1]&0xC0)==0x80) @1;else @2;)";
CM_ SG_ 2566868737 MCU_FF4F01_01_16 "电机1与控制器1状态 (原始算法: if((BYTE[0]&0xC0)==0x40) @0;else @1;)";
CM_ BO_ 2566872913 "ICM 仪表 / 绝缘监测, CAN ID 0x18FF5F51, PGN 0xFF5F, SA 0x51";
CM_ SG_ 2566872913 ICM_FF5F51_01_05 "电机侧直流母线电流 (原始算法: BYTE[4]*4-500)";
CM_ SG_ 2566872913 ICM_FF5F51_01_06 "电机侧直流母线电压 (原始算法: BYTE[3]*3.2)";
CM_ SG_ 2566872913 ICM_FF5F51_01_07 "续航里程 (原始算法: BYTE[5]*2)";
CM_ SG_ 2566872913 ICM_FF5F51_02_03 "系统准备好 (原始算法: if((BYTE[1]&0x03)==0x01) @0;else @1;)";
CM_ SG_ 2566872913 ICM_FF5F51_02_05 "车辆运行模式 (原始算法: if((BYTE[1]&0xC0)==0x40) @0;else @1;)";
CM_ SG_ 2566872913 ICM_FF5F51_02_06 "整车运行状况 (原始算法: if((BYTE[0]&0xC0)==0x40) @0;else @1;)";
CM_ SG_ 2566872913 ICM_FF5F51_02_0E "电机过热 (原始算法: if((BYTE[2]&0x30)==0x10) @0;else @1;)";
CM_ SG_ 2566872913 ICM_FF5F51_02_10 "钥匙启动反馈 (原始算法: if((BYTE[0]&0x03)==0x01) @0;else @1;)";
CM_ SG_ 2566872913 ICM_FF5F51_02_11 "电机超速 (原始算法: if((BYTE[2]&0x0C)==0x04) @0;else @1;)";
CM_ SG_ 2566872913 ICM_FF5F51_02_13 "预充电状态 (原始算法: if((BYTE[0]&0x30)==0x10) @0;else @1;)";
CM_ SG_ 2566872913 ICM_FF5F51_02_14 "低压欠压故障 (原始算法: if((BYTE[2]&0x03)==0x01) @0;else @1;)";
CM_ SG_ 2566872913 ICM_FF5F51_02_16 "跛行指示 (原始算法: if((BYTE[1]&0x30)==0x10) @0;else @1;)";
CM_ SG_ 2566872913 ICM_FF5F51_02_17 "水冷过温故障 (原始算法: if((BYTE[1]&0x0C)==0x04) @0;else @1;)";
CM_ SG_ 2566872913 ICM_FF5F51_02_19 "主接触器反馈 (原始算法: if((BYTE[0]&0x0C)==0x04) @0;else @1;)";
CM_ SG_ 2566872913 ICM_FF5F51_02_1A "电机故障 (原始算法: if((BYTE[2]&0xC0)==0x40) @0;else @1;)";
CM_ BO_ 2566876695 "ICM 仪表 / 绝缘监测, CAN ID 0x18FF6E17, PGN 0xFF6E, SA 0x17";
CM_ SG_ 2566876695 ICM_FF6E17_01_02 "当前车速 (原始算法: (BYTE[3]*256+BYTE[2])*0.00390625)";
CM_ SG_ 2566876695 ICM_FF6E17_01_08 "左侧制动回路气压值2 (原始算法: BYTE[0]*10)";
CM_ SG_ 2566876695 ICM_FF6E17_01_09 "右侧制动回路气压值2 (原始算法: BYTE[1]*10)";
CM_ SG_ 2566876695 ICM_FF6E17_02_01 "大灯信号 (原始算法: if((BYTE[5]&0xC0)==0x40) @0;else @1;)";
CM_ SG_ 2566876695 ICM_FF6E17_02_04 "前雾灯信号 (原始算法: if((BYTE[6]&0xC0)==0x40) @0;else @1;)";
CM_ SG_ 2566876695 ICM_FF6E17_02_07 "小灯信号 (原始算法: if((BYTE[5]&0x30)==0x10) @0;else @1;)";
CM_ SG_ 2566876695 ICM_FF6E17_02_09 "ABS失效故障 (原始算法: if((BYTE[4]&0xC0)==0x40) @0;else @1;)";
CM_ SG_ 2566876695 ICM_FF6E17_02_0A "后雾灯信号 (原始算法: if((BYTE[6]&0x30)==0x10) @0;else @1;)";
CM_ SG_ 2566876695 ICM_FF6E17_02_0B "电池充电策略 (原始算法: if((BYTE[4]&0x0C)==0x04) @0;else @1;)";
CM_ SG_ 2566876695 ICM_FF6E17_02_0C "水箱液位低故障 (原始算法: if((BYTE[4]&0x30)==0x10) @0;else @1;)";
CM_ BO_ 2566876951 "ICM 仪表 / 绝缘监测, CAN ID 0x18FF6F17, PGN 0xFF6F, SA 0x17";
CM_ SG_ 2566876951 ICM_FF6F17_01_03 "本次上电里程 (原始算法: (BYTE[5]*256+BYTE[4])*0.1)";
CM_ SG_ 2566876951 ICM_FF6F17_01_04 "总里程 (原始算法: (BYTE[3]<<24)+(BYTE[2]<<16)+(BYTE[1]<<8)+BYTE[0])";
CM_ SG_ 2566876951 ICM_FF6F17_02_08 "车辆转向信息 (原始算法: if((BYTE[6]&0xC0)==0x40) @0;else if((BYTE[6]&0xC0)==0x80) @1;else if((BYTE[6]&0xC0)==0xC0) @2;else @3;)";
CM_ SG_ 2566876951 ICM_FF6F17_02_0D "车门开灯信号 (原始算法: if((BYTE[7]&0x30)==0x10) @0;else if((BYTE[7]&0x30)==0x20) @1;else @2;)";
CM_ SG_ 2566876951 ICM_FF6F17_02_0F "主驾驶座位安全带信号 (原始算法: if((BYTE[6]&0x03)==0x01) @0;else @1;)";
CM_ SG_ 2566876951 ICM_FF6F17_02_12 "主驾驶座位压力传感器信号 (原始算法: if((BYTE[6]&0x30)==0x10) @0;else if((BYTE[6]&0x30)==0x20) @1;else @2;)";
CM_ SG_ 2566876951 ICM_FF6F17_02_15 "副驾驶座位安全带信号 (原始算法: if((BYTE[7]&0xC0)==0x40) @0;else @1;)";
CM_ SG_ 2566876951 ICM_FF6F17_02_18 "副驾驶座位压力传感器信号 (原始算法: if((BYTE[6]&0x0C)==0x04) @0;else if((BYTE[6]&0x0C)==0x08) @1;else @2;)";
CM_ BO_ 2566884701 "CPS 组合电源 (气泵/油泵), CAN ID 0x18FF8D5D, PGN 0xFF8D, SA 0x5D";
CM_ SG_ 2566884701 CPS_FF8D5D_00_02 "气泵 DCAC Life 值 (原始算法: BYTE[0]&0x0F)";
CM_ SG_ 2566884701 CPS_FF8D5D_00_04 "气泵DCAC电压输出 (原始算法: BYTE[3]*2)";
CM_ SG_ 2566884701 CPS_FF8D5D_00_06 "气泵温度 (原始算法: BYTE[4]-40)";
CM_ SG_ 2566884701 CPS_FF8D5D_01_0C "气泵DCAC驱动使能反馈 (原始算法: if((BYTE[0]&0x30)==0x10) @0;else @1;)";
CM_ SG_ 2566884701 CPS_FF8D5D_01_0D "气泵DCAC状态 (原始算法: if((BYTE[0]&0xC0)==0x40) @0;else @1;)";
CM_ SG_ 2566884701 CPS_FF8D5D_01_0E "气泵DCAC缺相故障 (原始算法: if((BYTE[1]&0x03)==0x01) @0;else @1;)";
CM_ SG_ 2566884701 CPS_FF8D5D_01_0F "气泵DCAC输入过流故障 (原始算法: if((BYTE[1]&0x0C)==0x04) @0;else @1;)";
CM_ SG_ 2566884701 CPS_FF8D5D_01_10 "气泵DCAC输入欠压故障 (原始算法: if((BYTE[1]&0x30)==0x10) @0;else @1;)";
CM_ SG_ 2566884701 CPS_FF8D5D_01_11 "气泵DCAC母线过压故障 (原始算法: if((BYTE[1]&0xC0)==0x40) @0;else @1;)";
CM_ SG_ 2566884701 CPS_FF8D5D_01_12 "气泵DCAC过温故障 (原始算法: if((BYTE[2]&0xC0)==0x40) @0;else @1;)";
CM_ BO_ 2566885213 "CPS 组合电源 (气泵/油泵), CAN ID 0x18FF8F5D, PGN 0xFF8F, SA 0x5D";
CM_ SG_ 2566885213 CPS_FF8F5D_00_01 "油泵Life值 (原始算法: BYTE[0]&0x0F)";
CM_ SG_ 2566885213 CPS_FF8F5D_00_03 "油泵DCAC电压输出 (原始算法: BYTE[3]*2)";
CM_ SG_ 2566885213 CPS_FF8F5D_00_05 "油泵电机温度 (原始算法: BYTE[4]-40)";
CM_ SG_ 2566885213 CPS_FF8F5D_01_04 "油泵DCAC驱动使能反馈 (原始算法: if((BYTE[0]&0x30)==0x10) @0;else @1;)";
CM_ SG_ 2566885213 CPS_FF8F5D_01_05 "油泵模块状态 (原始算法: if((BYTE[0]&0xC0)==0x40) @0;else @1;)";
CM_ SG_ 2566885213 CPS_FF8F5D_01_06 "油泵缺相故障 (原始算法: if((BYTE[1]&0x03)==0x01) @0;else @1;)";
CM_ SG_ 2566885213 CPS_FF8F5D_01_07 "油泵输入过流故障 (原始算法: if((BYTE[1]&0x0C)==0x04) @0;else @1;)";
CM_ SG_ 2566885213 CPS_FF8F5D_01_08 "油泵输入欠压故障 (原始算法: if((BYTE[1]&0x30)==0x10) @0;else @1;)";
CM_ SG_ 2566885213 CPS_FF8F5D_01_09 "油泵母线过压故障 (原始算法: if((BYTE[1]&0xC0)==0x40) @0;else @1;)";
CM_ SG_ 2566885213 CPS_FF8F5D_01_0A "油泵DCAC过温故障 (原始算法: if((BYTE[2]&0xC0)==0x40) @0;else @1;)";
CM_ BO_ 2566888021 "BMS 电池管理系统, CAN ID 0x18FF9A55, PGN 0xFF9A, SA 0x55";
CM_ SG_ 2566888021 BMS_FF9A55_00_09 "BMS硬件版本号 (原始算法: BYTE[0])";
CM_ SG_ 2566888021 BMS_FF9A55_00_0A "BMS软件版本号 (原始算法: BYTE[1])";
CM_ SG_ 2566888021 BMS_FF9A55_00_0B_Year "日期 [Year] (原始算法: BYTE[2])";
CM_ SG_ 2566888021 BMS_FF9A55_00_0B_Month "日期 [Month] (原始算法: BYTE[3])";
CM_ SG_ 2566888021 BMS_FF9A55_00_0B_Day "日期 [Day] (原始算法: BYTE[4])";
CM_ SG_ 2566888021 BMS_FF9A55_00_0C_Hour "时间 [Hour] (原始算法: BYTE[5])";
CM_ SG_ 2566888021 BMS_FF9A55_00_0C_Minute "时间 [Minute] (原始算法: BYTE[6])";
CM_ SG_ 2566888021 BMS_FF9A55_00_0C_Second "时间 [Second] (原始算法: BYTE[7])";
CM_ BO_ 2566888277 "BATTERY 电池箱 / 模组信息, CAN ID 0x18FF9B55, PGN 0xFF9B, SA 0x55";
CM_ SG_ 2566888277 BAT_FF9B_Block "帧块/子功能 (0x01-0x04 模组电压块, 0x10 温度块, 0x11-0x14 单体状态, 0xAA/0xBB 汇总) (原始算法: BYTE[0])";
CM_ SG_ 2566888277 BAT_FF9B_Packet "块内包序号 (原始算法: BYTE[1])";
CM_ SG_ 2566888277 BAT_FF9B_Data1 "数据1 (电压块: 单体电压 raw, x0.001 V; 温度块见 Data1_Temp) (原始算法: BYTE[2]+BYTE[3]*256)";
CM_ SG_ 2566888277 BAT_FF9B_Data2 "数据2 (电压块: 单体电压 raw, x0.001 V) (原始算法: BYTE[4]+BYTE[5]*256)";
CM_ SG_ 2566888277 BAT_FF9B_Data3 "数据3 (电压块: 单体电压 raw, x0.001 V) (原始算法: BYTE[6]+BYTE[7]*256)";
CM_ BO_ 2566888533 "BMS 电池管理系统, CAN ID 0x18FF9C55, PGN 0xFF9C, SA 0x55";
CM_ SG_ 2566888533 BMS_FF9C55_00_01 "最高温度电池所在箱体编号 (原始算法: BYTE[0])";
CM_ SG_ 2566888533 BMS_FF9C55_00_02 "最低温度电池所在箱体编号 (原始算法: BYTE[2])";
CM_ SG_ 2566888533 BMS_FF9C55_00_03 "最高电压电池所在箱体编号 (原始算法: BYTE[4])";
CM_ SG_ 2566888533 BMS_FF9C55_00_04 "最低电压电池所在箱体编号 (原始算法: BYTE[6])";
CM_ SG_ 2566888533 BMS_FF9C55_00_05 "最高温度电池单体编号 (原始算法: BYTE[1])";
CM_ SG_ 2566888533 BMS_FF9C55_00_06 "最低温度电池单体编号 (原始算法: BYTE[3])";
CM_ SG_ 2566888533 BMS_FF9C55_00_07 "最高电压电池单体编号 (原始算法: BYTE[5])";
CM_ SG_ 2566888533 BMS_FF9C55_00_08 "最低电压电池单体编号 (原始算法: BYTE[7])";
CM_ BO_ 2566888789 "BMS 电池管理系统, CAN ID 0x18FF9D55, PGN 0xFF9D, SA 0x55";
CM_ SG_ 2566888789 BMS_FF9D55_00_0F "电池侧母线电流高精度 (原始算法: ((BYTE[3]*256+BYTE[2])*0.02)-640)";
CM_ SG_ 2566888789 BMS_FF9D55_00_10 "电池侧母线电压高精度 (原始算法: (BYTE[1]*256+BYTE[0])*0.02)";
CM_ SG_ 2566888789 BMS_FF9D55_00_15 "电池最大允许充电电流 (原始算法: (BYTE[5]*256+BYTE[4])*0.01)";
CM_ SG_ 2566888789 BMS_FF9D55_00_16 "电池最大允许放电电流 (原始算法: (BYTE[7]*256+BYTE[6])*0.01)";
CM_ BO_ 2566889045 "BMS 电池管理系统, CAN ID 0x18FF9E55, PGN 0xFF9E, SA 0x55";
CM_ SG_ 2566889045 BMS_FF9E55_00_0E "绝缘电阻 (原始算法: BYTE[1]*256+BYTE[0])";
CM_ SG_ 2566889045 BMS_FF9E55_00_11 "电池最高温度 (原始算法: BYTE[2]-40)";
CM_ SG_ 2566889045 BMS_FF9E55_00_12 "电池最低温度 (原始算法: BYTE[3]-40)";
CM_ SG_ 2566889045 BMS_FF9E55_00_13 "电池最高电压 (原始算法: (BYTE[5]*256+BYTE[4])*0.001)";
CM_ SG_ 2566889045 BMS_FF9E55_00_14 "电池最低电压 (原始算法: (BYTE[7]*256+BYTE[6])*0.001)";
CM_ BO_ 2566889301 "BMS 电池管理系统, CAN ID 0x18FF9F55, PGN 0xFF9F, SA 0x55";
CM_ SG_ 2566889301 BMS_FF9F55_00_0D "电池SOC值 (原始算法: BYTE[5]*0.4)";
CM_ SG_ 2566889301 BMS_FF9F55_01_02 "SOC低状态 (原始算法: if((BYTE[1]&0x30)==0x10) @0;else if((BYTE[1]&0x30)==0x20) @1;else @2;)";
CM_ SG_ 2566889301 BMS_FF9F55_01_03 "电池绝缘故障 (原始算法: if((BYTE[0]&0x30)==0x20) @0;else if((BYTE[0]&0x30)==0x30) @1;else @2;)";
CM_ SG_ 2566889301 BMS_FF9F55_01_04 "慢充电激活 (原始算法: if((BYTE[4]&0xC0)==0x40) @0;else @1;)";
CM_ SG_ 2566889301 BMS_FF9F55_01_05 "SOC高状态 (原始算法: if((BYTE[1]&0xC0)==0x40) @0;else if((BYTE[1]&0xC0)==0x80) @1;else @2;)";
CM_ SG_ 2566889301 BMS_FF9F55_01_06 "慢充电故障 (原始算法: if((BYTE[4]&0x0C)==0x04) @0;else @1;)";
CM_ SG_ 2566889301 BMS_FF9F55_01_07 "快充电激活 (原始算法: if((BYTE[3]&0x03)==0x01) @0;else @1;)";
CM_ SG_ 2566889301 BMS_FF9F55_01_08 "电池低温状态 (原始算法: if((BYTE[2]&0x0C)==0x04) @0;else if((BYTE[2]&0x0C)==0x08) @1;else @2;)";
CM_ SG_ 2566889301 BMS_FF9F55_01_09 "快充电故障 (原始算法: if((BYTE[4]&0x30)==0x10) @0;else @1;)";
CM_ SG_ 2566889301 BMS_FF9F55_01_0A "电池主负继电器状态 (原始算法: if((BYTE[6]&0xC0)==0x40) @0;else @1;)";
CM_ SG_ 2566889301 BMS_FF9F55_01_0B "电池高温状态 (原始算法: if((BYTE[2]&0x30)==0x10) @0;else if((BYTE[2]&0x30)==0x20) @1;else if((BYTE[2]&0x30)==0x30) @2;else @3;)";
CM_ SG_ 2566889301 BMS_FF9F55_01_0C "BMS内部通讯故障 (原始算法: if((BYTE[3]&0x0C)==0x08) @0;else @1;)";
CM_ SG_ 2566889301 BMS_FF9F55_01_0D "电池状态 (原始算法: if((BYTE[0]&0xC0)==0x40) @0;else @1;)";
CM_ SG_ 2566889301 BMS_FF9F55_01_0E "单体低电压状态 (原始算法: if((BYTE[1]&0x03)==0x01) @0;else if((BYTE[1]&0x03)==0x02) @1;else if((BYTE[1]&0x03)==0x03) @2;else @3;)";
CM_ SG_ 2566889301 BMS_FF9F55_01_0F "热车状态 (原始算法: if((BYTE[0]&0x03)==0x01) @0;else @1;)";
CM_ SG_ 2566889301 BMS_FF9F55_01_10 "单体高电压状态 (原始算法: if((BYTE[1]&0x0C)==0x04) @0;else if((BYTE[1]&0x0C)==0x08) @1;else if((BYTE[1]&0x0C)==0x0C) @2;else @3;)";
CM_ SG_ 2566889301 BMS_FF9F55_01_11 "单体电压差 (原始算法: if((BYTE[2]&0xC0)==0x40) @0;else if((BYTE[2]&0xC0)==0x80) @1;else @2;)";
CM_ SG_ 2566889301 BMS_FF9F55_01_12 "放电电流状态 (原始算法: if((BYTE[3]&0x30)==0x10) @0;else if((BYTE[3]&0x30)==0x20) @1;else if((BYTE[3]&0x30)==0x30) @2;else @3;)";
CM_ SG_ 2566889301 BMS_FF9F55_01_13 "电池总电压低状态 (原始算法: if((BYTE[4]&0x03)==0x01) @0;else if((BYTE[4]&0x03)==0x02) @1;else @2;)";
CM_ SG_ 2566889301 BMS_FF9F55_01_14 "电池温度差 (原始算法: if((BYTE[2]&0x03)==0x01) @0;else if((BYTE[2]&0x03)==0x02) @1;else @2;)";
CM_ SG_ 2566889301 BMS_FF9F55_01_16 "电池总电压高状态 (原始算法: if((BYTE[0]&0x0C)==0x04) @0;else if((BYTE[0]&0x0C)==0x08) @1;else @2;)";
CM_ BO_ 2566893401 "ICM 仪表 / 绝缘监测, CAN ID 0x18FFAF59, PGN 0xFFAF, SA 0x59";
CM_ SG_ 2566893401 ICM_FFAF59_00_01 "绝缘电阻 (原始算法: BYTE[6]*256+BYTE[5])";
CM_ SG_ 2566893401 ICM_FFAF59_00_02 "绝缘检测仪状态字节 (原始算法: if((BYTE[7]&0x0F)==0x01) @0;else if((BYTE[7]&0x0F)==0x02) @1;else if((BYTE[7]&0x0F)==0x04) @2;else if((BYTE[7]&0x0F)==0x05) @3;else if((BYTE[7]&0x0F)==0x06) @4;else if((BYTE[7]&0x0F)==0x07) @5;else if((BYTE[7]&0x0F)==0x0F) @6;else @7;)";
CM_ SG_ 2566893401 ICM_FFAF59_00_03 "电池绝缘状态 (原始算法: if((BYTE[7]&0x30)==0x10) @0;else if((BYTE[7]&0x30)==0x20) @1;else if((BYTE[7]&0x30)==0x30) @2;else @3;)";
CM_ BO_ 2566897246 "AC 空调, CAN ID 0x18FFBE5E, PGN 0xFFBE, SA 0x5E";
CM_ SG_ 2566897246 AC_FFBE5E_02_06 "室外空气温度2 (原始算法: BYTE[3]-40)";
CM_ SG_ 2566897246 AC_FFBE5E_02_07 "PTC温度2 (原始算法: BYTE[4]-40)";
CM_ SG_ 2566897246 AC_FFBE5E_02_08 "实际空调空气温度/蒸发器温度2 (原始算法: BYTE[5]-40)";
CM_ BO_ 2566913290 "VCU 整车控制器, CAN ID 0x18FFFD0A, PGN 0xFFFD, SA 0x0A";
CM_ SG_ 2566913290 VCU_FFFD0A_00_01_Major "VCU软件版本号 [Major] (原始算法: BYTE[3])";
CM_ SG_ 2566913290 VCU_FFFD0A_00_01_Minor "VCU软件版本号 [Minor] (原始算法: BYTE[4])";
CM_ SG_ 2566913290 VCU_FFFD0A_00_01_Build "VCU软件版本号 [Build] (原始算法: BYTE[5])";
CM_ SG_ 2566913290 VCU_FFFD0A_00_02 "电机控制器软件版本号 (原始算法: BYTE[7])";
CM_ SG_ 2566913290 VCU_FFFD0A_00_04 "电机当前输出力矩百分比 (原始算法: BYTE[6]-125)";
CM_ SG_ 2566913290 VCU_FFFD0A_00_06 "油门踏板1 AD 值 (原始算法: BYTE[2]/255.0*100)";
CM_ BO_ 2566913546 "VCU 整车控制器, CAN ID 0x18FFFE0A, PGN 0xFFFE, SA 0x0A";
CM_ SG_ 2566913546 VCU_FFFE0A_00_03 "记录程序版本号 (原始算法: BYTE[4])";
CM_ SG_ 2566913546 VCU_FFFE0A_01_04 "DC-DC信号故障 (原始算法: if(BYTE[5]&0x01) @0;else @1;)";
CM_ SG_ 2566913546 VCU_FFFE0A_02_02 "主接触器开关 (原始算法: if(BYTE[1]&0x01) @0;else @1;)";
CM_ SG_ 2566913546 VCU_FFFE0A_02_04 "DC-DC开关 (原始算法: if(BYTE[2]&0x01) @0;else @1;)";
CM_ SG_ 2566913546 VCU_FFFE0A_02_05 "预充电开关 (原始算法: if(BYTE[0]&0x01) @0;else @1;)";
CM_ SG_ 2566913546 VCU_FFFE0A_02_06 "BMS、仪表供电12V开关 (原始算法: if(BYTE[3]&0x01) @0;else @1;)";
CM_ BO_ 2566913802 "VCU 整车控制器, CAN ID 0x18FFFF0A, PGN 0xFFFF, SA 0x0A";
CM_ SG_ 2566913802 VCU_FFFF0A_00_05 "档位 (原始算法: if((BYTE[3]&0x03)==0x01) @0;else if((BYTE[3]&0x03)==0x02) @1;else @2;)";
CM_ SG_ 2566913802 VCU_FFFF0A_00_07 "油门踏板 AD 值 (原始算法: BYTE[6]/255.0*100)";
CM_ SG_ 2566913802 VCU_FFFF0A_01_01 "钥匙ACC档 (原始算法: if(BYTE[0]&0x01) @0;else @1;)";
CM_ SG_ 2566913802 VCU_FFFF0A_01_02 "钥匙ST档 (原始算法: if(BYTE[2]&0x01) @0;else @1;)";
CM_ SG_ 2566913802 VCU_FFFF0A_01_03 "钥匙ON档 (原始算法: if(BYTE[1]&0x01) @0;else @1;)";
CM_ SG_ 2566913802 VCU_FFFF0A_02_01 "油门踏板开关 (原始算法: if(BYTE[5]&0x01) @0;else @1;)";
CM_ SG_ 2566913802 VCU_FFFF0A_02_03 "刹车踏板开关 (原始算法: if(BYTE[4]&0x01) @0;else @1;)";

VAL_ 2365529937 BMS_FF1F51_01_01 0 "不允许" 1 "允许" 2 "不允许" 3 "不允许";
VAL_ 2365534033 CPS_FF2F51_01_01 0 "无" 1 "有" 2 "无" 3 "无";
VAL_ 2365534033 CPS_FF2F51_01_02 0 "无" 1 "有" 2 "无" 3 "无";
VAL_ 2365534033 CPS_FF2F51_01_03 0 "无" 1 "有" 2 "无" 3 "无";
VAL_ 2365534033 CPS_FF2F51_01_0B 0 "无" 1 "有" 2 "无" 3 "无";
VAL_ 2365534033 CPS_FF2F51_01_13 0 "无" 1 "有" 2 "无" 3 "无";
VAL_ 2365538058 MCU_FF3F0A_00_10 0 "不许" 1 "允许" 2 "不许" 3 "不许";
VAL_ 2365538058 MCU_FF3F0A_00_11 0 "转矩" 1 "转速" 2 "转矩" 3 "转矩";
VAL_ 2365538058 MCU_FF3F0A_00_12 0 "不开" 1 "开启" 2 "不开" 3 "不开";
VAL_ 2365538058 MCU_FF3F0A_00_13 0 "未激活" 1 "激活" 2 "未激活" 3 "未激活";
VAL_ 2365538058 MCU_FF3F0A_00_14 0 "未合" 1 "闭合" 2 "未合" 3 "未合";
VAL_ 2365538058 MCU_FF3F0A_00_15 0 "D档" 1 "D档" 2 "N档" 3 "D档" 4 "R档" 5 "D档" 6 "D档" 7 "D档";
VAL_ 2365554513 AC_FF7F51_03_01 0 "无" 1 "有" 2 "无" 3 "无";
VAL_ 2365554513 AC_FF7F51_03_02 0 "关闭" 1 "打开" 2 "关闭" 3 "关闭";
VAL_ 2550255831 BMSW_01D0D7_01_01 0 "正常" 85 "故障";
VAL_ 2550265081 ADAS_01F4F9_02_01 0 "正常" 2 "锁车";
VAL_ 2550265081 ADAS_01F4F9_02_02 0 "在线" 2 "故障";
VAL_ 2565865553 ICM_F00051_02_02 0 "无效" 1 "有效" 2 "无效" 3 "无效";
VAL_ 2566832977 ICM_FEC351_01_0B 0 "关" 1 "开" 2 "故障" 3 "关";
VAL_ 2566832977 ICM_FEC351_01_0C 0 "关" 1 "开" 2 "故障" 3 "关";
VAL_ 2566832977 ICM_FEC351_01_0D 0 "关" 1 "开" 2 "故障" 3 "关";
VAL_ 2566868225 MCU_FF4D01_00_06 0 "不放电" 1 "放电" 2 "放电完成" 3 "放电故障";
VAL_ 2566868225 MCU_FF4D01_01_08 0 "正常" 1 "正常" 2 "二级" 3 "正常";
VAL_ 2566868225 MCU_FF4D01_01_0B 0 "正常" 1 "一级" 2 "正常" 3 "正常";
VAL_ 2566868225 MCU_FF4D01_01_0E 0 "正常" 1 "一级" 2 "二级" 3 "正常";
VAL_ 2566868225 MCU_FF4D01_01_13 0 "正常" 1 "一级" 2 "二级" 3 "正常";
VAL_ 2566868481 MCU_FF4E01_01_01 0 "正常" 1 "一级" 2 "二级" 3 "正常";
VAL_ 2566868481 MCU_FF4E01_01_02 0 "正常" 1 "正常" 2 "二级" 3 "正常";
VAL_ 2566868481 MCU_FF4E01_01_04 0 "正常" 1 "一级" 2 "二级" 3 "正常";
VAL_ 2566868481 MCU_FF4E01_01_05 0 "正常" 1 "正常" 2 "二级" 3 "正常";
VAL_ 2566868481 MCU_FF4E01_01_06 0 "正常" 1 "一级" 2 "二级" 3 "正常";
VAL_ 2566868481 MCU_FF4E01_01_0A 0 "正常" 1 "正常" 2 "二级" 3 "正常";
VAL_ 2566868481 MCU_FF4E01_01_0D 0 "正常" 1 "一级" 2 "二级" 3 "正常";
VAL_ 2566868481 MCU_FF4E01_01_10 0 "正常" 1 "一级" 2 "二级" 3 "正常";
VAL_ 2566868481 MCU_FF4E01_01_11 0 "正常" 1 "一级" 2 "正常" 3 "正常";
VAL_ 2566868481 MCU_FF4E01_01_12 0 "正常" 1 "一级" 2 "二级" 3 "正常";
VAL_ 2566868481 MCU_FF4E01_01_14 0 "正常" 1 "正常" 2 "二级" 3 "正常";
VAL_ 2566868481 MCU_FF4E01_01_15 0 "正常" 1 "正常" 2 "二级" 3 "正常";
VAL_ 2566868737 MCU_FF4F01_01_03 0 "正常" 1 "正常" 2 "二级" 3 "正常";
VAL_ 2566868737 MCU_FF4F01_01_07 0 "不动" 1 "可动" 2 "不动" 3 "不动";
VAL_ 2566868737 MCU_FF4F01_01_09 0 "正常" 1 "正常" 2 "二级" 3 "正常";
VAL_ 2566868737 MCU_FF4F01_01_0C 0 "正常" 1 "一级" 2 "二级" 3 "正常";
VAL_ 2566868737 MCU_FF4F01_01_0F 0 "正常" 1 "一级" 2 "二级" 3 "正常";
VAL_ 2566868737 MCU_FF4F01_01_16 0 "故障" 1 "正常" 2 "故障" 3 "故障";
VAL_ 2566872913 ICM_FF5F51_02_03 0 "没有" 1 "已好" 2 "没有" 3 "没有";
VAL_ 2566872913 ICM_FF5F51_02_05 0 "运动" 1 "经济" 2 "运动" 3 "运动";
VAL_ 2566872913 ICM_FF5F51_02_06 0 "不可行" 1 "可行" 2 "不可行" 3 "不可行";
VAL_ 2566872913 ICM_FF5F51_02_0E 0 "正常" 1 "过热" 2 "正常" 3 "正常";
VAL_ 2566872913 ICM_FF5F51_02_10 0 "不启动" 1 "启动" 2 "不启动" 3 "不启动";
VAL_ 2566872913 ICM_FF5F51_02_11 0 "正常" 1 "超速" 2 "正常" 3 "正常";
VAL_ 2566872913 ICM_FF5F51_02_13 0 "未预充" 1 "预充" 2 "未预充" 3 "未预充";
VAL_ 2566872913 ICM_FF5F51_02_14 0 "正常" 1 "故障" 2 "正常" 3 "正常";
VAL_ 2566872913 ICM_FF5F51_02_16 0 "正常" 1 "灯亮" 2 "正常" 3 "正常";
VAL_ 2566872913 ICM_FF5F51_02_17 0 "正常" 1 "故障" 2 "正常" 3 "正常";
VAL_ 2566872913 ICM_FF5F51_02_19 0 "断开" 1 "闭合" 2 "断开" 3 "断开";
VAL_ 2566872913 ICM_FF5F51_02_1A 0 "正常" 1 "故障" 2 "正常" 3 "正常";
VAL_ 2566876695 ICM_FF6E17_02_01 0 "关" 1 "开" 2 "关" 3 "关";
VAL_ 2566876695 ICM_FF6E17_02_04 0 "关" 1 "开" 2 "关" 3 "关";
VAL_ 2566876695 ICM_FF6E17_02_07 0 "关" 1 "开" 2 "关" 3 "关";
VAL_ 2566876695 ICM_FF6E17_02_09 0 "正常" 1 "故障" 2 "正常" 3 "正常";
VAL_ 2566876695 ICM_FF6E17_02_0A 0 "关" 1 "开" 2 "关" 3 "关";
VAL_ 2566876695 ICM_FF6E17_02_0B 0 "慢充" 1 "快充" 2 "慢充" 3 "慢充";
VAL_ 2566876695 ICM_FF6E17_02_0C 0 "正常" 1 "故障" 2 "正常" 3 "正常";
VAL_ 2566876951 ICM_FF6F17_02_08 0 "未转" 1 "左转" 2 "右转" 3 "双闪";
VAL_ 2566876951 ICM_FF6F17_02_0D 0 "未开" 1 "左开" 2 "右开" 3 "未开";
VAL_ 2566876951 ICM_FF6F17_02_0F 0 "未系" 1 "已系" 2 "未系" 3 "未系";
VAL_ 2566876951 ICM_FF6F17_02_12 0 "无信号" 1 "有信号" 2 "故障" 3 "无信号";
VAL_ 2566876951 ICM_FF6F17_02_15 0 "未系" 1 "已系" 2 "未系" 3 "未系";
VAL_ 2566876951 ICM_FF6F17_02_18 0 "无信号" 1 "有信号" 2 "故障" 3 "无信号";
VAL_ 2566884701 CPS_FF8D5D_01_0C 0 "无" 1 "准备" 2 "无" 3 "无";
VAL_ 2566884701 CPS_FF8D5D_01_0D 0 "故障" 1 "正常" 2 "故障" 3 "故障";
VAL_ 2566884701 CPS_FF8D5D_01_0E 0 "正常" 1 "故障" 2 "正常" 3 "正常";
VAL_ 2566884701 CPS_FF8D5D_01_0F 0 "正常" 1 "故障" 2 "正常" 3 "正常";
VAL_ 2566884701 CPS_FF8D5D_01_10 0 "正常" 1 "故障" 2 "正常" 3 "正常";
VAL_ 2566884701 CPS_FF8D5D_01_11 0 "正常" 1 "故障" 2 "正常" 3 "正常";
VAL_ 2566884701 CPS_FF8D5D_01_12 0 "正常" 1 "故障" 2 "正常" 3 "正常";
VAL_ 2566885213 CPS_FF8F5D_01_04 0 "无" 1 "准备" 2 "无" 3 "无";
VAL_ 2566885213 CPS_FF8F5D_01_05 0 "故障" 1 "正常" 2 "故障" 3 "故障";
VAL_ 2566885213 CPS_FF8F5D_01_06 0 "正常" 1 "故障" 2 "正常" 3 "正常";
VAL_ 2566885213 CPS_FF8F5D_01_07 0 "正常" 1 "故障" 2 "正常" 3 "正常";
VAL_ 2566885213 CPS_FF8F5D_01_08 0 "正常" 1 "故障" 2 "正常" 3 "正常";
VAL_ 2566885213 CPS_FF8F5D_01_09 0 "正常" 1 "故障" 2 "正常" 3 "正常";
VAL_ 2566885213 CPS_FF8F5D_01_0A 0 "正常" 1 "故障" 2 "正常" 3 "正常";
VAL_ 2566889301 BMS_FF9F55_01_02 0 "正常" 1 "一级" 2 "二级" 3 "正常";
VAL_ 2566889301 BMS_FF9F55_01_03 0 "正常" 1 "正常" 2 "二级" 3 "三级";
VAL_ 2566889301 BMS_FF9F55_01_04 0 "未连" 1 "已连" 2 "未连" 3 "未连";
VAL_ 2566889301 BMS_FF9F55_01_05 0 "正常" 1 "一级" 2 "二级" 3 "正常";
VAL_ 2566889301 BMS_FF9F55_01_06 0 "正常" 1 "故障" 2 "正常" 3 "正常";
VAL_ 2566889301 BMS_FF9F55_01_07 0 "未连" 1 "已连" 2 "未连" 3 "未连";
VAL_ 2566889301 BMS_FF9F55_01_08 0 "正常" 1 "一级" 2 "二级" 3 "正常";
VAL_ 2566889301 BMS_FF9F55_01_09 0 "正常" 1 "故障" 2 "正常" 3 "正常";
VAL_ 2566889301 BMS_FF9F55_01_0A 0 "未闭合" 1 "闭合" 2 "未闭合" 3 "未闭合";
VAL_ 2566889301 BMS_FF9F55_01_0B 0 "正常" 1 "一级" 2 "二级" 3 "三级";
VAL_ 2566889301 BMS_FF9F55_01_0C 0 "正常" 1 "正常" 2 "二级" 3 "正常";
VAL_ 2566889301 BMS_FF9F55_01_0D 0 "故障" 1 "正常" 2 "故障" 3 "故障";
VAL_ 2566889301 BMS_FF9F55_01_0E 0 "正常" 1 "一级" 2 "二级" 3 "三级";
VAL_ 2566889301 BMS_FF9F55_01_0F 0 "允许" 1 "不许" 2 "允许" 3 "允许";
VAL_ 2566889301 BMS_FF9F55_01_10 0 "正常" 1 "一级" 2 "二级" 3 "三级";
VAL_ 2566889301 BMS_FF9F55_01_11 0 "正常" 1 "一级" 2 "二级" 3 "正常";
VAL_ 2566889301 BMS_FF9F55_01_12 0 "正常" 1 "一级" 2 "二级" 3 "三级";
VAL_ 2566889301 BMS_FF9F55_01_13 0 "正常" 1 "低" 2 "过低" 3 "正常";
VAL_ 2566889301 BMS_FF9F55_01_14 0 "正常" 1 "一级" 2 "二级" 3 "正常";
VAL_ 2566889301 BMS_FF9F55_01_16 0 "正常" 1 "一级" 2 "二级" 3 "正常";
VAL_ 2566893401 ICM_FFAF59_00_02 0 "--" 1 "表示正在质检" 2 "工作正常" 3 "--" 4 "接线故障" 5 "高压正极对地绝缘电阻较小" 6 "高压负极对地绝缘电阻较小" 7 "设备故障" 8 "--" 9 "--" 10 "--" 11 "--" 12 "--" 13 "--" 14 "--" 15 "无效";
VAL_ 2566893401 ICM_FFAF59_00_03 0 "正常" 1 "一级警告 绝缘电阻小于500K" 2 "二级警告 绝缘电阻小于80K" 3 "无效";
VAL_ 2566913546 VCU_FFFE0A_01_04 0 "有故障" 1 "无故障";
VAL_ 2566913546 VCU_FFFE0A_02_02 0 "关" 1 "开";
VAL_ 2566913546 VCU_FFFE0A_02_04 0 "关" 1 "开";
VAL_ 2566913546 VCU_FFFE0A_02_05 0 "关" 1 "开";
VAL_ 2566913546 VCU_FFFE0A_02_06 0 "关" 1 "开";
VAL_ 2566913802 VCU_FFFF0A_00_05 0 "N档" 1 "D档" 2 "R档" 3 "N档";
VAL_ 2566913802 VCU_FFFF0A_01_01 0 "关" 1 "开";
VAL_ 2566913802 VCU_FFFF0A_01_02 0 "关" 1 "开";
VAL_ 2566913802 VCU_FFFF0A_01_03 0 "关" 1 "开";
VAL_ 2566913802 VCU_FFFF0A_02_01 0 "关" 1 "开";
VAL_ 2566913802 VCU_FFFF0A_02_03 0 "关" 1 "开";

BA_DEF_ "BusType" STRING ;
BA_DEF_ "ProtocolType" STRING ;
BA_DEF_ BO_ "VFrameFormat" ENUM "StandardCAN","ExtendedCAN","reserved","J1939PG";
BA_DEF_DEF_ "BusType" "CAN";
BA_DEF_DEF_ "ProtocolType" "J1939";
BA_DEF_DEF_ "VFrameFormat" 3;
